# nrf9160 register map
Vendor: Nordic Semiconductor; Series: nrf91; File version: 1
CPU: CM33 r0p4, little endian, MPU, FPU, 3 interrupt priority bits, 69 interrupts
Registers are 32-bit, read-write, reset 0x0 unless marked. A register's access mark holds for its fields unless they carry their own. Offsets are from the block's base; [hi:lo] are bit positions; lines under a group give offsets from that group; {n}, {i} and the like mark numbered series; 'fields as' and 'values as' point back to an identical list.

## VMC_NS — Volatile Memory controller 0
Base 0x4003A000
Same registers: VMC_S 0x5003A000
{0x600+0x10*i} RAM[{i}] (i=0..7) group — Unspecified
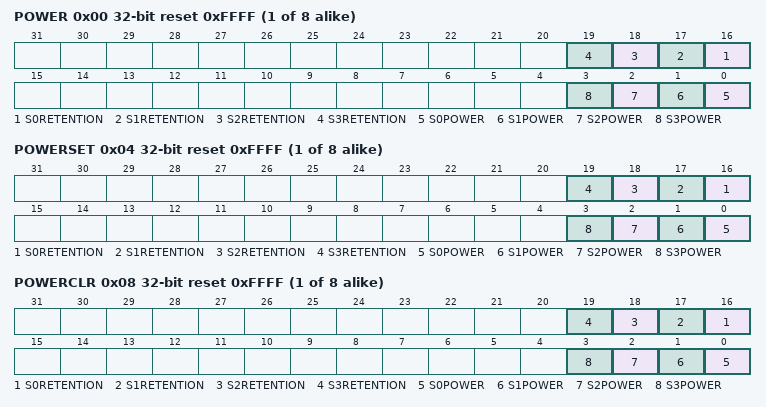
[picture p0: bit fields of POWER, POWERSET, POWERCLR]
  0x00 POWER reset 0xFFFF — Description cluster: RAMn power control register
    [all] fields
      0=Off; 1=On
    [n+16] S{n}RETENTION (n=0..3) — Keep retention on RAM section S{n} of RAM n when RAM section is switched off
    [n] S{n}POWER (n=0..3) — Keep RAM section S{n} of RAM n on or off in System ON mode
  0x04 POWERSET wo reset 0xFFFF — Description cluster: RAMn power control set register
    [all] fields
      1=On
    [n+16] S{n}RETENTION (n=0..3) — Keep retention on RAM section S{n} of RAM n when RAM section is switched off
    [n] S{n}POWER (n=0..3) — Keep RAM section S{n} of RAM n on or off in System ON mode
  0x08 POWERCLR wo reset 0xFFFF — Description cluster: RAMn power control clear register
    [all] fields
      1=Off
    [n+16] S{n}RETENTION (n=0..3) — Keep retention on RAM section S{n} of RAM n when RAM section is switched off
    [n] S{n}POWER (n=0..3) — Keep RAM section S{n} of RAM n on or off in System ON mode

## CC_HOST_RGF_S — CRYPTOCELL HOST_RGF interface
Base 0x50840000
0x1A38 HOST_CRYPTOKEY_SEL — AES hardware key select
  [1:0] HOST_CRYPTOKEY_SEL — Select the source of the HW key that is used by the AES engine
    0=K_DR (Use device root key K_DR from CRYPTOCELL AO power domain); 1=K_PRTL (Use hard-coded RTL key K_PRTL); 2=Session (Use provided session key)
0x1A4C HOST_IOT_KPRTL_LOCK — This write-once register is the K_PRTL lock register. When this register is set, K_PRTL cannot be used and a zeroed key will be used instead. The value of this register is saved in the CRYPTOCELL AO power domain.
  [0] HOST_IOT_KPRTL_LOCK — This register is the K_PRTL lock register. When this register is set, K_PRTL cannot be used and a zeroed key will be used instead. The value of this register is saved in the CRYPTOCELL AO power domain.
    0=Disabled (K_PRTL can be selected for use from register HOST_CRYPTOKEY_SEL); 1=Enabled (K_PRTL has been locked until next power-on reset (POR). If K_PRTL is selected anyway, a zeroed key will be used instead.)
0x1A50 HOST_IOT_KDR0 — This register holds bits 31:0 of K_DR. The value of this register is saved in the CRYPTOCELL AO power domain. Reading from this address returns the K_DR valid status indicating if K_DR is successfully retained.
  [31:0] HOST_IOT_KDR0 — Write: K_DR bits 31:0. Read: 0x00000000 when 128-bit K_DR key value is not yet retained in the CRYPTOCELL AO power domain. Read: 0x00000001 when 128-bit K_DR key value is successfully retained in the CRYPTOCELL AO power domain.
{0x1A50+4i} HOST_IOT_KDR{i} wo (i=1..3) — This register holds bits {32i+31}:{32i} of K_DR. The value of this register is saved in the CRYPTOCELL AO power domain.
  [31:0] HOST_IOT_KDR{i} — K_DR bits {32i+31}:{32i}
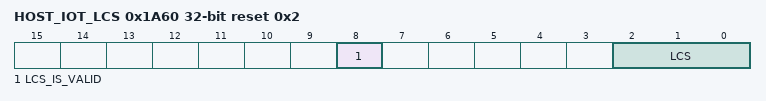
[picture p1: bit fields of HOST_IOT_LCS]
0x1A60 HOST_IOT_LCS reset 0x2 — Controls lifecycle state (LCS) for CRYPTOCELL subsystem
  [8] LCS_IS_VALID — Read-only field. Indicates if CRYPTOCELL LCS has been successfully configured since last reset.
    0=Invalid (Valid LCS not yet retained in the CRYPTOCELL AO power domain); 1=Valid LCS successfully retained in the CRYPTOCELL AO power domain
  [2:0] LCS — Lifecycle state value. This field is write-once per reset.
    0=Debug (CC310 operates in debug mode); 2=Secure (CC310 operates in secure mode)

## CRYPTOCELL_S — ARM TrustZone CryptoCell register interface
Base 0x50840000; alternate view of CC_HOST_RGF_S
0x500 ENABLE — Enable CRYPTOCELL subsystem
  [0] ENABLE — Enable or disable the CRYPTOCELL subsystem
    0=Disabled (CRYPTOCELL subsystem disabled); 1=Enabled (CRYPTOCELL subsystem enabled.)

## P0_NS — GPIO Port 0
Base 0x40842500
Same registers: P0_S 0x50842500
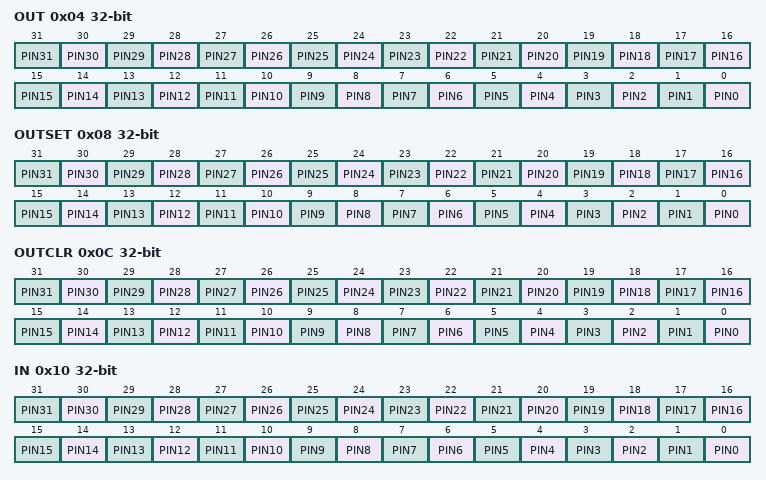
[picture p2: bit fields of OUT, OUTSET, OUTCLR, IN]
0x04 OUT — Write GPIO port
  [all] fields
    0=Low (Pin driver is low); 1=High (Pin driver is high)
  [n] PIN{n} (n=0..31)
0x08 OUTSET write-1-sets — Set individual bits in GPIO port
  [all] fields
    on read: 0=Low (Read: pin driver is low); 1=High (Read: pin driver is high) | on write: 1=Set (Write: writing a '1' sets the pin high; writing a '0' has no effect)
  [n] PIN{n} (n=0..31)
0x0C OUTCLR write-1-clears — Clear individual bits in GPIO port
  [all] fields
    on read: 0=Low (Read: pin driver is low); 1=High (Read: pin driver is high) | on write: 1=Clear (Write: writing a '1' sets the pin low; writing a '0' has no effect)
  [n] PIN{n} (n=0..31)
0x10 IN ro — Read GPIO port
  [all] fields
    0=Low (Pin input is low); 1=High (Pin input is high)
  [n] PIN{n} (n=0..31)
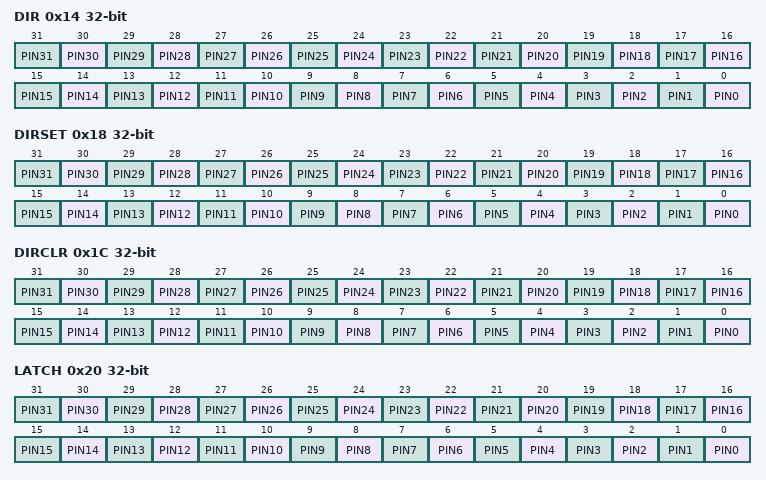
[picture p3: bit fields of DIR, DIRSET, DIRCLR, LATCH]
0x14 DIR — Direction of GPIO pins
  [all] fields
    0=Input (Pin set as input); 1=Output (Pin set as output)
  [n] PIN{n} (n=0..31)
0x18 DIRSET write-1-sets
  [all] fields
    on read: 0=Input (Read: pin set as input); 1=Output (Read: pin set as output) | on write: 1=Set (Write: writing a '1' sets pin to output; writing a '0' has no effect)
  [n] PIN{n} (n=0..31) — Set as output pin {n}
0x1C DIRCLR write-1-clears — DIR clear register
  [all] fields
    on read: 0=Input (Read: pin set as input); 1=Output (Read: pin set as output) | on write: 1=Clear (Write: writing a '1' sets pin to input; writing a '0' has no effect)
  [n] PIN{n} (n=0..31) — Set as input pin {n}
0x20 LATCH — Latch register indicating what GPIO pins that have met the criteria set in the PIN_CNF[n].SENSE registers
  [all] fields
    0=NotLatched (Criteria has not been met); 1=Latched (Criteria has been met)
  [n] PIN{n} (n=0..31) — Status on whether PIN{n} has met criteria set in PIN_CNF{n}.SENSE register. Write '1' to clear.
0x24 DETECTMODE — Select between default DETECT signal behavior and LDETECT mode (For non-secure pin only)
  [0] DETECTMODE — Select between default DETECT signal behavior and LDETECT mode
    0=Default (DETECT directly connected to PIN DETECT signals); 1=LDETECT (Use the latched LDETECT behavior)
0x28 DETECTMODE_SEC — Select between default DETECT signal behavior and LDETECT mode (For secure pin only)
  fields as DETECTMODE
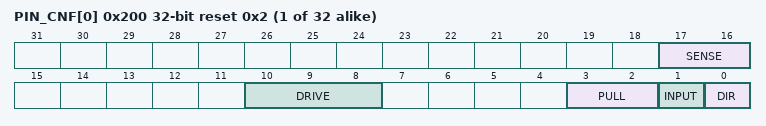
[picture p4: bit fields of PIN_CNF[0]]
{0x200+4i} PIN_CNF[{i}] (i=0..31) reset 0x2 — Description collection: Configuration of GPIO pins
  [17:16] SENSE — Pin sensing mechanism
    0=Disabled; 2=High (Sense for high level); 3=Low (Sense for low level)
  [10:8] DRIVE — Drive configuration
    0=S0S1 (Standard '0', standard '1'); 1=H0S1 (High drive '0', standard '1'); 2=S0H1 (Standard '0', high drive '1'); 3=H0H1 (High drive '0', high 'drive '1''); 4=D0S1 (Disconnect '0', standard '1' (normally used for wired-or connections)); 5=D0H1 (Disconnect '0', high drive '1' (normally used for wired-or connections)); 6=S0D1 (Standard '0', disconnect '1' (normally used for wired-and connections)); 7=H0D1 (High drive '0', disconnect '1' (normally used for wired-and connections))
  [3:2] PULL — Pull configuration
    0=Disabled (No pull); 1=Pull down on pin; 3=Pull up on pin
  [1] INPUT — Connect or disconnect input buffer
    0=Connect input buffer; 1=Disconnect input buffer
  [0] DIR — Pin direction. Same physical register as DIR register
    0=Input (Configure pin as an input pin); 1=Output (Configure pin as an output pin)
